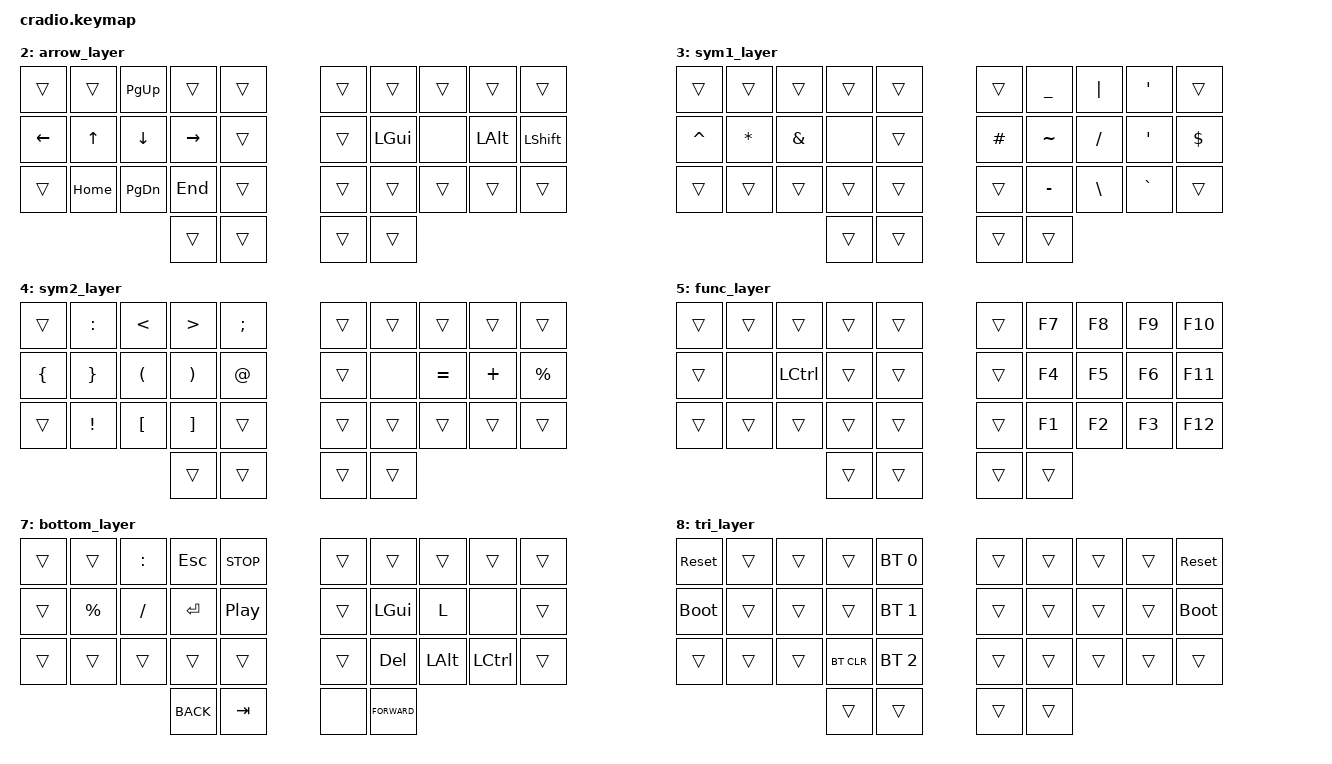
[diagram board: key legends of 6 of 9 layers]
// Copyright (c) 2022 The Z0MK Contributors
// SPDX-License-Identifier: MIT
#define ZMK_POINTING_DEFAULT_MOVE_VAL 1500  // default: 600
#define ZMK_POINTING_DEFAULT_SCRL_VAL 20    // default: 10

#include <dt-bindings/zmk/pointing.h>
#include <behaviors.dtsi>
#include <dt-bindings/zmk/keys.h>
#include <dt-bindings/zmk/bt.h>

// Home row mods macro
#define HRML(k1,k2,k3,k4) &mt LSHFT k1  &lt 5 k2  &lt 1 k3  &lt 3 k4
#define HRMR(k1,k2,k3,k4) &lt 4 k1  &lt 2 k2  &lt 6 k3  &mt RSHFT k4

/ {
    behaviors {
        ht: hold_tap {
            compatible = "zmk,behavior-hold-tap";
            #binding-cells = <2>;
            flavor = "tap-preferred";
            tapping-term-ms = <220>;
            quick-tap-ms = <150>;
            require-prior-idle-ms = <100>;
            bindings = <&kp>, <&kp>;
        };
    };

    conditional_layers {
        compatible = "zmk,conditional-layers";
        tri_layer {
            if-layers = <1 2>;
            then-layer = <8>;
        };
    };

    keymap {
        compatible = "zmk,keymap";
        default_layer {
            bindings = <
        //╭──────────┬──────────┬──────────┬──────────┬──────────╮   ╭──────────┬──────────┬──────────┬──────────┬──────────╮
        //│  Q       │  W       │  E       │  R       │  T       │   │  Y       │  U       │  I       │  O       │  P       │
            &kp Q      &kp W      &kp E      &kp R      &kp T          &kp Y      &kp U      &kp I      &kp O      &kp P
        //├──────────┼──────────┼──────────┼──────────┼──────────┤   ├──────────┼──────────┼──────────┼──────────┼──────────┤
        //│  A       │  S       │  D       │  F       │  G       │   │  H       │  J       │  K       │  L       │ :;       │
            HRML(A,        S,         D,         F)     &kp G          &kp H      HRMR(J,        K,         L,        COLON)
        //├──────────┼──────────┼──────────┼──────────┼──────────┤   ├──────────┼──────────┼──────────┼──────────┼──────────┤
        //│  Z       │  X       │  C       │  V       │  B       │   │  N       │  M       │ , <      │ . >      │ / ?      │
            &kp Z      &mt LCTRL X &mt LALT C      &kp V      &kp B          &kp N      &kp M      &mt LALT COMMA  &mt LCTRL DOT    &kp FSLH
        //╰──────────┴──────────┴──────────┼──────────┼──────────┤   ├──────────┼──────────┼──────────┴──────────┴──────────╯
                                            &lt 2 TAB   &kp BSPC      &lt 7 SPACE &kp END
        //                                 ╰──────────┴──────────╯   ╰──────────┴──────────╯
            >;
        };
	mouse_layer {
            bindings = <
        //╭──────────┬──────────┬──────────┬──────────┬──────────╮   ╭──────────┬──────────┬──────────┬──────────┬──────────╮
        //│  Q       │  W	│  E	   │  R       │  T	 │   │  Y	│  U	   │  I       │  O	 │  P       │
            &trans      &trans	  &trans      &trans	&trans          &trans	  &mkp MB1  &msc SCRL_UP &mkp MB2   &trans
        //├──────────┼──────────┼──────────┼──────────┼──────────┤   ├──────────┼──────────┼──────────┼──────────┼──────────┤
        //│  A       │  S	│  D	   │  F       │  G	 │   │  H	│  J	   │  K       │  L	 │ :;       │
	    &trans	&mkp MB2 &none	     &mkp MB1	&trans		&trans	  &mmv MOVE_LEFT  &mmv MOVE_DOWN &mmv MOVE_UP &mmv MOVE_RIGHT			
        //│  Z       │  X	│  C	   │  V       │  B	 │   │  N	│  M	   │ , <      │ . >	 │ / ?      │
            &trans     &trans	  &trans      &trans	&trans          &trans	  &msc SCRL_LEFT&msc SCRL_DOWN&msc SCRL_RIGHT
        //╰──────────┴──────────┴──────────┼──────────┼──────────┤   ├──────────┼──────────┼──────────┴──────────┴──────────╯
                                            &trans      &trans          &trans    &trans   
        //                                 ╰──────────┴──────────╯   ╰──────────┴──────────╯  
            >;
	};
	arrow_layer {
            bindings = <
        //╭──────────┬──────────┬──────────┬──────────┬──────────╮   ╭──────────┬──────────┬──────────┬──────────┬──────────╮
        //│ INSERT   │  1	│  2	   │  3       │          │   │ HOME     │ PAGE DN  │ PAGE UP  │ END	 │  :
       &trans   &trans    &kp PG_UP	 &trans    &trans                  &trans     &trans    &trans    &trans      &trans
        //├──────────┼──────────┼──────────┼──────────┼──────────┤   ├──────────┼──────────┼──────────┼──────────┼──────────┤
        //│ LEFT     │  UP	│   DOWN   │  RIGHT   │          │   │ LEFT     │ DOWN     │ UP       │ RIGHT    │  ;       │
            &kp LEFT   &kp UP     &kp DOWN   &kp RIGHT   &trans        &trans     &kp LGUI   &none     &kp LALT   &kp LSHFT
        //├──────────┼──────────┼──────────┼──────────┼──────────┤   ├──────────┼──────────┼──────────┼──────────┼──────────┤
        //│ CAPS     │  7	│  8	   │  9       │  DELETE  │   │          │          │          │          │          │
            &trans    &kp HOME   &kp PG_DN   &kp END    &trans          &trans     &trans    &trans    &trans	   &trans
        //╰──────────┴──────────┴──────────┼──────────┼──────────┤   ├──────────┼──────────┼──────────┴──────────┴──────────╯
                                             &trans     &trans         &trans     &trans
        //                                 ╰──────────┴──────────╯   ╰──────────┴──────────╯
            >;
	};

	sym1_layer {
            bindings = <
        //╭──────────┬──────────┬──────────┬──────────┬──────────╮   ╭──────────┬──────────┬──────────┬──────────┬──────────╮
        //│ INSERT   │  1	│  2	   │  3       │          │   │ HOME     │ PAGE DN  │ PAGE UP  │ END	 │  :       │
            &trans    &trans     &trans     &trans     &trans         &trans   &kp UNDER  &kp PIPE  &kp SQT    &trans
        //├──────────┼──────────┼──────────┼──────────┼──────────┤   ├──────────┼──────────┼──────────┼──────────┼──────────┤
        //│ 0        │  1	│  2	   │  6       │          │   │ LEFT     │ DOWN     │ UP       │ RIGHT    │  ;       │
            &kp CARET  &kp ASTRK   &kp AMPS     &none     &trans         &kp HASH   &kp TILDE   &kp FSLH   &kp SQT   &kp DLLR
        //├──────────┼──────────┼──────────┼──────────┼──────────┤   ├──────────┼──────────┼──────────┼──────────┼──────────┤
        //│ CAPS     │  7	│  8	   │  9       │  DELETE  │   │          │          │          │          │          │
          &trans    &trans     &trans     &trans     &trans            &trans     &kp MINUS &kp BSLH    &kp GRAVE   &trans  
	//╰──────────┴──────────┴──────────┼──────────┼──────────┤   ├──────────┼──────────┼──────────┴──────────┴──────────╯
                                             &trans     &trans         &trans     &trans
        //                                 ╰──────────┴──────────╯   ╰──────────┴──────────╯
            >;
	};
	

        sym2_layer {
            bindings = <
        //╭──────────┬──────────┬──────────┬──────────┬──────────╮   ╭──────────┬──────────┬──────────┬──────────┬──────────╮
        //│ INSERT   │  1       │  2       │  3       │          │   │ HOME     │ PAGE DN  │ PAGE UP  │ END      │  :       
       &trans	&kp COLON    &kp LT      &kp GT    &kp SEMI              &trans     &trans    &trans    &trans      &trans
        //├──────────┼──────────┼──────────┼──────────┼──────────┤   ├──────────┼──────────┼──────────┼──────────┼──────────┤
        //│ LEFT     │  UP      │   DOWN   │  RIGHT   │          │   │ LEFT     │ DOWN     │ UP       │ RIGHT    │  ;       │
            &kp LBRC   &kp RBRC     &kp LPAR   &kp RPAR   &kp AT        &trans     &none   &kp EQUAL     &kp PLUS   &kp PRCNT
        //├──────────┼──────────┼──────────┼──────────┼──────────┤   ├──────────┼──────────┼──────────┼──────────┼──────────┤
        //│ CAPS     │  !       │  [{      │  9       │  DELETE  │   │          │          │          │          │          │
            &trans    &kp EXCL   &kp LBKT   &kp RBKT    &trans          &trans     &trans    &trans    &trans      &trans
        //╰──────────┴──────────┴──────────┼──────────┼──────────┤   ├──────────┼──────────┼──────────┴──────────┴──────────╯
                                             &trans     &trans         &trans     &trans
        //                                 ╰──────────┴──────────╯   ╰──────────┴──────────╯
            >;
        };

        func_layer {
            bindings = <
        //╭──────────┬──────────┬──────────┬──────────┬──────────╮   ╭──────────┬──────────┬──────────┬──────────┬──────────╮
        //│          │  [       │  {       │  }       │          │   │  ^       │  (       │  )       │  ]       │  ~       │
            &trans     &trans        &trans   &trans   &trans         &trans  &kp F7   &kp F8   &kp F9   &kp F10
        //├──────────┼──────────┼──────────┼──────────┼──────────┤   ├──────────┼──────────┼──────────┼──────────┼──────────┤
        //│  !       │  @       │  #       │  $       │  %       │   │  *       │  -       │  =       │  \       │  `       │
            &trans      &none     &kp LCTRL   &trans    &trans         &trans      &kp F4  &kp F5  &kp F6  &kp F11
        //├──────────┼──────────┼──────────┼──────────┼──────────┤   ├──────────┼──────────┼──────────┼──────────┼──────────┤
        //│          │          │          │          │          │   │  &       │  _       │  +       │  │       │          │
            &trans     &trans     &trans     &trans     &trans         &trans     &kp F1     &kp F2     &kp F3     &kp F12
        //╰──────────┴──────────┴──────────┼──────────┼──────────┤   ├──────────┼──────────┼──────────┴──────────┴──────────╯
                                             &trans     &trans         &trans     &trans
        //                                 ╰──────────┴──────────╯   ╰──────────┴──────────╯
            >;
        };
        numpad_layer {
            bindings = <
        //╭──────────┬──────────┬──────────┬──────────┬──────────╮   ╭──────────┬──────────┬──────────┬──────────┬──────────╮
        //│ INSERT   │  1       │  2       │  3       │          │   │ HOME     │ PAGE DN  │ PAGE UP  │ END      │  :       │
            &kp FSLH   &kp N7     &kp N8     &kp N9     &kp PLUS         &trans   &trans     &trans     &trans     &trans
        //├──────────┼──────────┼──────────┼──────────┼──────────┤   ├──────────┼──────────┼──────────┼──────────┼──────────┤
        //│ 0        │  1       │  2       │  6       │          │   │ LEFT     │ DOWN     │ UP       │ RIGHT    │  ;       │
            &kp N0  &kp N1   &kp N2     &kp N3     &kp MINUS            &trans    &trans     &trans     &none       &trans
        //├──────────┼──────────┼──────────┼──────────┼──────────┤   ├──────────┼──────────┼──────────┼──────────┼──────────┤
        //│ CAPS     │  7       │  8       │  9       │  DELETE  │   │          │          │          │          │          │
          &kp ASTRK    &kp N4 &kp N5 &kp N6 &kp EQUAL&trans   &trans     &trans	&trans  &trans  &trans 
        //╰──────────┴──────────┴──────────┼──────────┼──────────┤   ├──────────┼──────────┼──────────┴──────────┴──────────╯
                                             &trans     &trans         &trans     &trans
        //                                 ╰──────────┴──────────╯   ╰──────────┴──────────╯
            >;
        };
        bottom_layer {
	    bindings = <
        //╭──────────┬──────────┬──────────┬──────────┬──────────╮   ╭──────────┬──────────┬──────────┬──────────┬──────────╮
        //│ INSERT   │  1       │  2       │  3       │          │   │ HOME     │ PAGE DN  │ PAGE UP  │ END      │  :       │
            &trans   &trans    &kp COLON     &kp ESC     &kp C_STOP         &trans   &trans     &trans	&trans   &trans
        //├──────────┼──────────┼──────────┼──────────┼──────────┤   ├──────────┼──────────┼──────────┼──────────┼──────────┤
        //│ 0        │  1       │  2       │  6       │          │   │ LEFT     │ DOWN     │ UP       │ RIGHT    │  ;       │
            &trans   &kp PRCNT   &kp FSLH     &kp ENTER     &kp C_PP     &trans    &kp LGUI     &kp L     &none       &trans
        //├──────────┼──────────┼──────────┼──────────┼──────────┤   ├──────────┼──────────┼──────────┼──────────┼──────────┤
        //│ CAPS     │  7       │  8       │  9       │  DELETE  │   │          │          │          │          │          │
          &trans        &trans 		&trans   &trans     &trans          &trans &kp DEL  &kp LALT  &kp LCTRL  &trans     
        //╰──────────┴──────────┴──────────┼──────────┼──────────┤   ├──────────┼──────────┼──────────┴──────────┴──────────╯
                                             &kp K_BACK     &kp TAB         &none     &kp K_FORWARD
        //                                 ╰──────────┴──────────╯   ╰──────────┴──────────╯
            >;
	};

        tri_layer {
            bindings = <
        //╭──────────┬──────────┬──────────┬──────────┬──────────╮   ╭──────────┬──────────┬──────────┬──────────┬──────────╮
        //│ RESET    │          │          │          │PROFILE 0 │   │          │          │          │          │  RESET   │
           &sys_reset  &trans     &trans     &trans    &bt BT_SEL 0    &trans     &trans     &trans     &trans    &sys_reset
        //├──────────┼──────────┼──────────┼──────────┼──────────┤   ├──────────┼──────────┼──────────┼──────────┼──────────┤
        //│BOOTLOADER│          │          │          │PROFILE 1 │   │          │          │          │          │BOOTLOADER│
          &bootloader  &trans     &trans     &trans    &bt BT_SEL 1    &trans     &trans     &trans     &trans    &bootloader
        //├──────────┼──────────┼──────────┼──────────┼──────────┤   ├──────────┼──────────┼──────────┼──────────┼──────────┤
        //│          │          │          │ CLEAR BT │PROFILE 2 │   │          │          │          │          │          │
            &trans     &trans     &trans    &bt BT_CLR &bt BT_SEL 2    &trans     &trans     &trans     &trans     &trans
        //╰──────────┴──────────┴──────────┼──────────┼──────────┤   ├──────────┼──────────┼──────────┴──────────┴──────────╯
                                             &trans     &trans         &trans     &trans
        //                                 ╰──────────┴──────────╯   ╰──────────┴──────────╯
            >;
        };
    };
};
